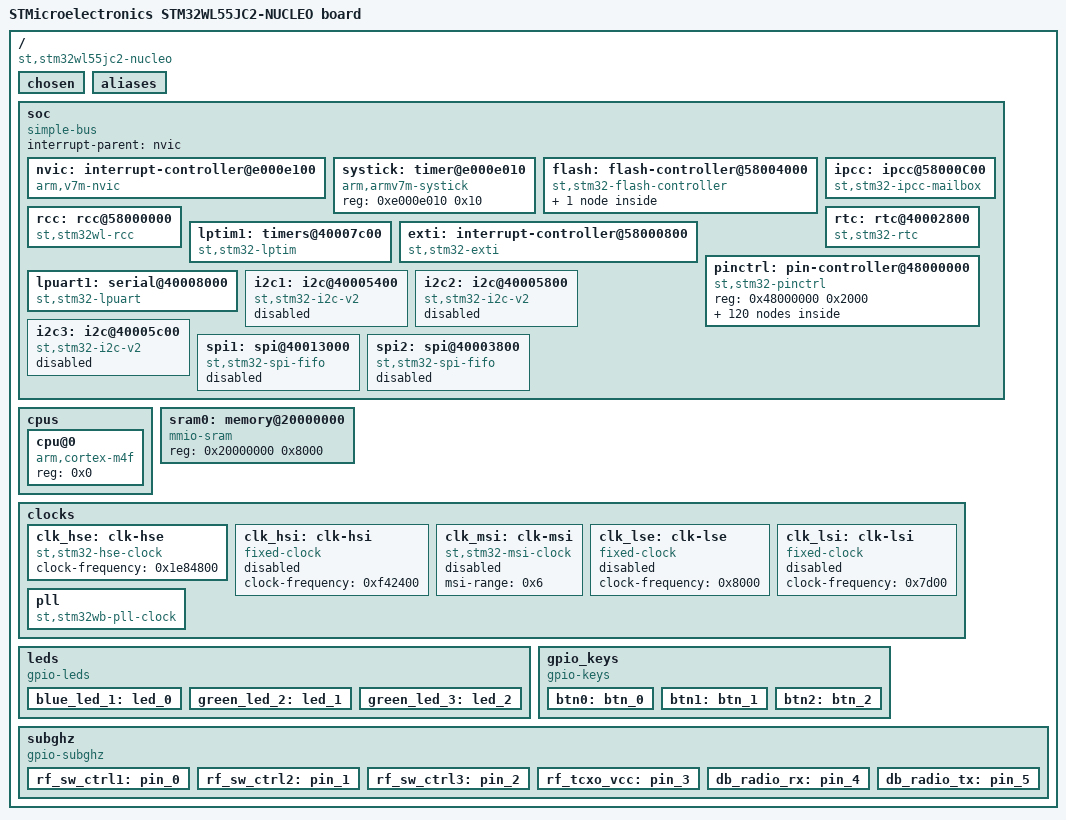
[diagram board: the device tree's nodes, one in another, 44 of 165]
/dts-v1/;

/ {
	#address-cells = < 0x1 >;
	#size-cells = < 0x1 >;
	model = "STMicroelectronics STM32WL55JC2-NUCLEO board";
	compatible = "st,stm32wl55jc2-nucleo";
	chosen {
		zephyr,flash-controller = &flash;
		zephyr,console = &lpuart1;
		zephyr,shell-uart = &lpuart1;
		zephyr,sram = &sram0;
		zephyr,flash = &flash0;
		zephyr,code-partition = &flash0;
	};
	aliases {
		led0 = &green_led_2;
		sw0 = &btn0;
		sw1 = &btn1;
		sw2 = &btn2;
		rfswctrl1 = &rf_sw_ctrl1;
		rfswctrl2 = &rf_sw_ctrl2;
		rfswctrl3 = &rf_sw_ctrl3;
		rftcxovcc = &rf_tcxo_vcc;
		dbradiorx = &db_radio_rx;
		dbradiotx = &db_radio_tx;
	};
	soc {
		#address-cells = < 0x1 >;
		#size-cells = < 0x1 >;
		compatible = "simple-bus";
		interrupt-parent = < &nvic >;
		ranges;
		nvic: interrupt-controller@e000e100 {
			compatible = "arm,v7m-nvic";
			reg = < 0xe000e100 0xc00 >;
			interrupt-controller;
			#interrupt-cells = < 0x2 >;
			arm,num-irq-priority-bits = < 0x4 >;
			phandle = < 0x1 >;
		};
		systick: timer@e000e010 {
			compatible = "arm,armv7m-systick";
			reg = < 0xe000e010 0x10 >;
		};
		flash: flash-controller@58004000 {
			compatible = "st,stm32-flash-controller", "st,stm32wl-flash-controller";
			label = "FLASH_CTRL";
			reg = < 0x58004000 0x400 >;
			interrupts = < 0x4 0x0 >;
			#address-cells = < 0x1 >;
			#size-cells = < 0x1 >;
			flash0: flash@8000000 {
				compatible = "soc-nv-flash";
				label = "FLASH_STM32";
				write-block-size = < 0x8 >;
				erase-block-size = < 0x800 >;
				reg = < 0x8000000 0x20000 >;
			};
		};
		ipcc: ipcc@58000C00 {
			compatible = "st,stm32-ipcc-mailbox";
			#address-cells = < 0x1 >;
			#size-cells = < 0x0 >;
			reg = < 0x58000c00 0x10 >;
			clocks = < &rcc 0x6 0x100000 >;
			interrupts = < 0x2d 0x0 >, < 0x2e 0x0 >;
			interrupt-names = "rxo", "txf";
			status = "okay";
			label = "IPCC";
			buffer = < 0x20000000 0xff >;
		};
		rcc: rcc@58000000 {
			compatible = "st,stm32wl-rcc";
			#clock-cells = < 0x2 >;
			reg = < 0x58000000 0x400 >;
			label = "STM32_CLK_RCC";
			clocks = < &pll >;
			clock-frequency = < 0x2dc6c00 >;
			cpu1-prescaler = < 0x1 >;
			cpu2-prescaler = < 0x1 >;
			ahb3-prescaler = < 0x1 >;
			apb1-prescaler = < 0x1 >;
			apb2-prescaler = < 0x1 >;
			phandle = < 0x2 >;
		};
		rtc: rtc@40002800 {
			compatible = "st,stm32-rtc";
			reg = < 0x40002800 0x400 >;
			interrupts = < 0x2a 0x0 >;
			clocks = < &rcc 0x2 0x10000000 >;
			prescaler = < 0x8000 >;
			status = "okay";
			label = "RTC_0";
		};
		lptim1: timers@40007c00 {
			compatible = "st,stm32-lptim";
			clocks = < &rcc 0x2 0x48000000 >;
			#address-cells = < 0x1 >;
			#size-cells = < 0x0 >;
			reg = < 0x40007c00 0x400 >;
			interrupts = < 0x27 0x0 >;
			interrupt-names = "wakeup";
			status = "okay";
			label = "LPTIM_1";
		};
		exti: interrupt-controller@58000800 {
			compatible = "st,stm32-exti";
			interrupt-controller;
			#interrupt-cells = < 0x1 >;
			reg = < 0x58000800 0x400 >;
		};
		pinctrl: pin-controller@48000000 {
			compatible = "st,stm32-pinctrl";
			#address-cells = < 0x1 >;
			#size-cells = < 0x1 >;
			reg = < 0x48000000 0x2000 >;
			gpioa: gpio@48000000 {
				compatible = "st,stm32-gpio";
				gpio-controller;
				#gpio-cells = < 0x2 >;
				reg = < 0x48000000 0x400 >;
				clocks = < &rcc 0x1 0x1 >;
				label = "GPIOA";
				phandle = < 0xe >;
			};
			gpiob: gpio@48000400 {
				compatible = "st,stm32-gpio";
				gpio-controller;
				#gpio-cells = < 0x2 >;
				reg = < 0x48000400 0x400 >;
				clocks = < &rcc 0x1 0x2 >;
				label = "GPIOB";
				phandle = < 0xd >;
			};
			gpioc: gpio@48000800 {
				compatible = "st,stm32-gpio";
				gpio-controller;
				#gpio-cells = < 0x2 >;
				reg = < 0x48000800 0x400 >;
				clocks = < &rcc 0x1 0x4 >;
				label = "GPIOC";
				phandle = < 0xf >;
			};
			gpioh: gpio@48001c00 {
				compatible = "st,stm32-gpio";
				gpio-controller;
				#gpio-cells = < 0x2 >;
				reg = < 0x48001c00 0x400 >;
				clocks = < &rcc 0x1 0x80 >;
				label = "GPIOH";
			};
			adc_in6_pa10: adc_in6_pa10 {
				pinmux = < 0xa10 >;
			};
			adc_in7_pa11: adc_in7_pa11 {
				pinmux = < 0xb10 >;
			};
			adc_in8_pa12: adc_in8_pa12 {
				pinmux = < 0xc10 >;
			};
			adc_in9_pa13: adc_in9_pa13 {
				pinmux = < 0xd10 >;
			};
			adc_in10_pa14: adc_in10_pa14 {
				pinmux = < 0xe10 >;
			};
			adc_in11_pa15: adc_in11_pa15 {
				pinmux = < 0xf10 >;
			};
			adc_in5_pb1: adc_in5_pb1 {
				pinmux = < 0x1110 >;
			};
			adc_in4_pb2: adc_in4_pb2 {
				pinmux = < 0x1210 >;
			};
			adc_in2_pb3: adc_in2_pb3 {
				pinmux = < 0x1310 >;
			};
			adc_in3_pb4: adc_in3_pb4 {
				pinmux = < 0x1410 >;
			};
			adc_in0_pb13: adc_in0_pb13 {
				pinmux = < 0x1d10 >;
			};
			adc_in1_pb14: adc_in1_pb14 {
				pinmux = < 0x1e10 >;
			};
			dac_out1_pa10: dac_out1_pa10 {
				pinmux = < 0xa10 >;
			};
			i2c1_scl_pa9: i2c1_scl_pa9 {
				pinmux = < 0x904 >;
				bias-pull-up;
				drive-open-drain;
			};
			i2c1_scl_pb6: i2c1_scl_pb6 {
				pinmux = < 0x1604 >;
				bias-pull-up;
				drive-open-drain;
			};
			i2c1_scl_pb8: i2c1_scl_pb8 {
				pinmux = < 0x1804 >;
				bias-pull-up;
				drive-open-drain;
			};
			i2c2_scl_pa12: i2c2_scl_pa12 {
				pinmux = < 0xc04 >;
				bias-pull-up;
				drive-open-drain;
				phandle = < 0x6 >;
			};
			i2c2_scl_pb15: i2c2_scl_pb15 {
				pinmux = < 0x1f04 >;
				bias-pull-up;
				drive-open-drain;
			};
			i2c3_scl_pa7: i2c3_scl_pa7 {
				pinmux = < 0x704 >;
				bias-pull-up;
				drive-open-drain;
			};
			i2c3_scl_pb10: i2c3_scl_pb10 {
				pinmux = < 0x1a04 >;
				bias-pull-up;
				drive-open-drain;
			};
			i2c3_scl_pb13: i2c3_scl_pb13 {
				pinmux = < 0x1d04 >;
				bias-pull-up;
				drive-open-drain;
			};
			i2c3_scl_pc0: i2c3_scl_pc0 {
				pinmux = < 0x2004 >;
				bias-pull-up;
				drive-open-drain;
			};
			i2c1_sda_pa10: i2c1_sda_pa10 {
				pinmux = < 0xa04 >;
				bias-pull-up;
				drive-open-drain;
			};
			i2c1_sda_pb7: i2c1_sda_pb7 {
				pinmux = < 0x1704 >;
				bias-pull-up;
				drive-open-drain;
			};
			i2c1_sda_pb9: i2c1_sda_pb9 {
				pinmux = < 0x1904 >;
				bias-pull-up;
				drive-open-drain;
			};
			i2c2_sda_pa11: i2c2_sda_pa11 {
				pinmux = < 0xb04 >;
				bias-pull-up;
				drive-open-drain;
				phandle = < 0x7 >;
			};
			i2c2_sda_pa15: i2c2_sda_pa15 {
				pinmux = < 0xf04 >;
				bias-pull-up;
				drive-open-drain;
			};
			i2c3_sda_pb4: i2c3_sda_pb4 {
				pinmux = < 0x1404 >;
				bias-pull-up;
				drive-open-drain;
			};
			i2c3_sda_pb11: i2c3_sda_pb11 {
				pinmux = < 0x1b04 >;
				bias-pull-up;
				drive-open-drain;
			};
			i2c3_sda_pb14: i2c3_sda_pb14 {
				pinmux = < 0x1e04 >;
				bias-pull-up;
				drive-open-drain;
			};
			i2c3_sda_pc1: i2c3_sda_pc1 {
				pinmux = < 0x2104 >;
				bias-pull-up;
				drive-open-drain;
			};
			i2s2_ck_pa8: i2s2_ck_pa8 {
				pinmux = < 0x805 >;
				slew-rate = "very-high-speed";
			};
			i2s2_ck_pa9: i2s2_ck_pa9 {
				pinmux = < 0x905 >;
				slew-rate = "very-high-speed";
			};
			i2s2_ck_pb10: i2s2_ck_pb10 {
				pinmux = < 0x1a05 >;
				slew-rate = "very-high-speed";
			};
			i2s2_ck_pb13: i2s2_ck_pb13 {
				pinmux = < 0x1d05 >;
				slew-rate = "very-high-speed";
			};
			i2s2_sd_pa10: i2s2_sd_pa10 {
				pinmux = < 0xa05 >;
			};
			i2s2_sd_pb15: i2s2_sd_pb15 {
				pinmux = < 0x1f05 >;
			};
			i2s2_sd_pc1: i2s2_sd_pc1 {
				pinmux = < 0x2103 >;
			};
			i2s2_sd_pc3: i2s2_sd_pc3 {
				pinmux = < 0x2305 >;
			};
			i2s2_ws_pa9: i2s2_ws_pa9 {
				pinmux = < 0x903 >;
			};
			i2s2_ws_pb9: i2s2_ws_pb9 {
				pinmux = < 0x1905 >;
			};
			i2s2_ws_pb12: i2s2_ws_pb12 {
				pinmux = < 0x1c05 >;
			};
			spi1_miso_pa6: spi1_miso_pa6 {
				pinmux = < 0x605 >;
				bias-pull-down;
				phandle = < 0xa >;
			};
			spi1_miso_pa11: spi1_miso_pa11 {
				pinmux = < 0xb05 >;
				bias-pull-down;
			};
			spi1_miso_pb4: spi1_miso_pb4 {
				pinmux = < 0x1405 >;
				bias-pull-down;
			};
			spi2_miso_pa5: spi2_miso_pa5 {
				pinmux = < 0x503 >;
				bias-pull-down;
			};
			spi2_miso_pb14: spi2_miso_pb14 {
				pinmux = < 0x1e05 >;
				bias-pull-down;
			};
			spi2_miso_pc2: spi2_miso_pc2 {
				pinmux = < 0x2205 >;
				bias-pull-down;
			};
			spi1_mosi_pa7: spi1_mosi_pa7 {
				pinmux = < 0x705 >;
				bias-pull-down;
				phandle = < 0xb >;
			};
			spi1_mosi_pa12: spi1_mosi_pa12 {
				pinmux = < 0xc05 >;
				bias-pull-down;
			};
			spi1_mosi_pb5: spi1_mosi_pb5 {
				pinmux = < 0x1505 >;
				bias-pull-down;
			};
			spi2_mosi_pa10: spi2_mosi_pa10 {
				pinmux = < 0xa05 >;
				bias-pull-down;
			};
			spi2_mosi_pb15: spi2_mosi_pb15 {
				pinmux = < 0x1f05 >;
				bias-pull-down;
			};
			spi2_mosi_pc1: spi2_mosi_pc1 {
				pinmux = < 0x2103 >;
				bias-pull-down;
			};
			spi2_mosi_pc3: spi2_mosi_pc3 {
				pinmux = < 0x2305 >;
				bias-pull-down;
			};
			spi1_nss_pa4: spi1_nss_pa4 {
				pinmux = < 0x405 >;
				bias-pull-up;
				phandle = < 0x8 >;
			};
			spi1_nss_pa15: spi1_nss_pa15 {
				pinmux = < 0xf05 >;
				bias-pull-up;
			};
			spi1_nss_pb2: spi1_nss_pb2 {
				pinmux = < 0x1205 >;
				bias-pull-up;
			};
			spi2_nss_pa9: spi2_nss_pa9 {
				pinmux = < 0x903 >;
				bias-pull-up;
			};
			spi2_nss_pb9: spi2_nss_pb9 {
				pinmux = < 0x1905 >;
				bias-pull-up;
			};
			spi2_nss_pb12: spi2_nss_pb12 {
				pinmux = < 0x1c05 >;
				bias-pull-up;
			};
			spi1_sck_pa1: spi1_sck_pa1 {
				pinmux = < 0x105 >;
				slew-rate = "very-high-speed";
			};
			spi1_sck_pa5: spi1_sck_pa5 {
				pinmux = < 0x505 >;
				slew-rate = "very-high-speed";
				phandle = < 0x9 >;
			};
			spi1_sck_pb3: spi1_sck_pb3 {
				pinmux = < 0x1305 >;
				slew-rate = "very-high-speed";
			};
			spi2_sck_pa8: spi2_sck_pa8 {
				pinmux = < 0x805 >;
				slew-rate = "very-high-speed";
			};
			spi2_sck_pa9: spi2_sck_pa9 {
				pinmux = < 0x905 >;
				slew-rate = "very-high-speed";
			};
			spi2_sck_pb10: spi2_sck_pb10 {
				pinmux = < 0x1a05 >;
				slew-rate = "very-high-speed";
			};
			spi2_sck_pb13: spi2_sck_pb13 {
				pinmux = < 0x1d05 >;
				slew-rate = "very-high-speed";
			};
			tim1_ch1n_pa7: tim1_ch1n_pa7 {
				pinmux = < 0x701 >;
			};
			tim1_ch1_pa8: tim1_ch1_pa8 {
				pinmux = < 0x801 >;
			};
			tim1_ch2_pa9: tim1_ch2_pa9 {
				pinmux = < 0x901 >;
			};
			tim1_ch3_pa10: tim1_ch3_pa10 {
				pinmux = < 0xa01 >;
			};
			tim1_ch4_pa11: tim1_ch4_pa11 {
				pinmux = < 0xb01 >;
			};
			tim1_ch2n_pb8: tim1_ch2n_pb8 {
				pinmux = < 0x1801 >;
			};
			tim1_ch3n_pb9: tim1_ch3n_pb9 {
				pinmux = < 0x1901 >;
			};
			tim1_ch1n_pb13: tim1_ch1n_pb13 {
				pinmux = < 0x1d01 >;
			};
			tim1_ch2n_pb14: tim1_ch2n_pb14 {
				pinmux = < 0x1e01 >;
			};
			tim1_ch3n_pb15: tim1_ch3n_pb15 {
				pinmux = < 0x1f01 >;
			};
			tim2_ch1_pa0: tim2_ch1_pa0 {
				pinmux = < 0x1 >;
			};
			tim2_ch2_pa1: tim2_ch2_pa1 {
				pinmux = < 0x101 >;
			};
			tim2_ch3_pa2: tim2_ch3_pa2 {
				pinmux = < 0x201 >;
			};
			tim2_ch4_pa3: tim2_ch4_pa3 {
				pinmux = < 0x301 >;
			};
			tim2_ch1_pa5: tim2_ch1_pa5 {
				pinmux = < 0x501 >;
			};
			tim2_ch1_pa15: tim2_ch1_pa15 {
				pinmux = < 0xf01 >;
			};
			tim2_ch2_pb3: tim2_ch2_pb3 {
				pinmux = < 0x1301 >;
			};
			tim2_ch3_pb10: tim2_ch3_pb10 {
				pinmux = < 0x1a01 >;
			};
			tim2_ch4_pb11: tim2_ch4_pb11 {
				pinmux = < 0x1b01 >;
			};
			tim16_ch1_pa6: tim16_ch1_pa6 {
				pinmux = < 0x60e >;
			};
			tim16_ch1n_pb6: tim16_ch1n_pb6 {
				pinmux = < 0x160e >;
			};
			tim16_ch1_pb8: tim16_ch1_pb8 {
				pinmux = < 0x180e >;
			};
			tim17_ch1_pa7: tim17_ch1_pa7 {
				pinmux = < 0x70e >;
			};
			tim17_ch1n_pb7: tim17_ch1n_pb7 {
				pinmux = < 0x170e >;
			};
			tim17_ch1_pb9: tim17_ch1_pb9 {
				pinmux = < 0x190e >;
			};
			lpuart1_cts_pa6: lpuart1_cts_pa6 {
				pinmux = < 0x608 >;
				bias-pull-up;
				drive-open-drain;
			};
			usart1_cts_pa11: usart1_cts_pa11 {
				pinmux = < 0xb07 >;
				bias-pull-up;
				drive-open-drain;
			};
			usart1_cts_pb4: usart1_cts_pb4 {
				pinmux = < 0x1407 >;
				bias-pull-up;
				drive-open-drain;
			};
			lpuart1_cts_pb13: lpuart1_cts_pb13 {
				pinmux = < 0x1d08 >;
				bias-pull-up;
				drive-open-drain;
			};
			usart2_cts_pa0: usart2_cts_pa0 {
				pinmux = < 0x7 >;
				bias-pull-up;
				drive-open-drain;
			};
			lpuart1_rts_pa1: lpuart1_rts_pa1 {
				pinmux = < 0x108 >;
				bias-pull-up;
				drive-open-drain;
			};
			usart1_rts_pa12: usart1_rts_pa12 {
				pinmux = < 0xc07 >;
				bias-pull-up;
				drive-open-drain;
			};
			lpuart1_rts_pb1: lpuart1_rts_pb1 {
				pinmux = < 0x1108 >;
				bias-pull-up;
				drive-open-drain;
			};
			usart1_rts_pb3: usart1_rts_pb3 {
				pinmux = < 0x1307 >;
				bias-pull-up;
				drive-open-drain;
			};
			lpuart1_rts_pb12: lpuart1_rts_pb12 {
				pinmux = < 0x1c08 >;
				bias-pull-up;
				drive-open-drain;
			};
			usart2_rts_pa1: usart2_rts_pa1 {
				pinmux = < 0x107 >;
				bias-pull-up;
				drive-open-drain;
			};
			lpuart1_rx_pa3: lpuart1_rx_pa3 {
				pinmux = < 0x308 >;
				phandle = < 0x5 >;
			};
			usart1_rx_pa10: usart1_rx_pa10 {
				pinmux = < 0xa07 >;
			};
			usart1_rx_pb7: usart1_rx_pb7 {
				pinmux = < 0x1707 >;
			};
			lpuart1_rx_pb10: lpuart1_rx_pb10 {
				pinmux = < 0x1a08 >;
			};
			lpuart1_rx_pc0: lpuart1_rx_pc0 {
				pinmux = < 0x2008 >;
			};
			usart2_rx_pa3: usart2_rx_pa3 {
				pinmux = < 0x307 >;
			};
			lpuart1_tx_pa2: lpuart1_tx_pa2 {
				pinmux = < 0x208 >;
				bias-pull-up;
				phandle = < 0x4 >;
			};
			usart1_tx_pa9: usart1_tx_pa9 {
				pinmux = < 0x907 >;
				bias-pull-up;
			};
			usart1_tx_pb6: usart1_tx_pb6 {
				pinmux = < 0x1607 >;
				bias-pull-up;
			};
			lpuart1_tx_pb11: lpuart1_tx_pb11 {
				pinmux = < 0x1b08 >;
				bias-pull-up;
			};
			lpuart1_tx_pc1: lpuart1_tx_pc1 {
				pinmux = < 0x2108 >;
				bias-pull-up;
			};
			usart2_tx_pa2: usart2_tx_pa2 {
				pinmux = < 0x207 >;
				bias-pull-up;
			};
		};
		lpuart1: serial@40008000 {
			compatible = "st,stm32-lpuart", "st,stm32-uart";
			reg = < 0x40008000 0x400 >;
			clocks = < &rcc 0x4 0x1 >;
			interrupts = < 0x26 0x0 >;
			status = "okay";
			label = "LPUART_1";
			pinctrl-0 = < &lpuart1_tx_pa2 &lpuart1_rx_pa3 >;
			current-speed = < 0x1c200 >;
		};
		i2c1: i2c@40005400 {
			compatible = "st,stm32-i2c-v2";
			clock-frequency = < 0x186a0 >;
			#address-cells = < 0x1 >;
			#size-cells = < 0x0 >;
			reg = < 0x40005400 0x400 >;
			clocks = < &rcc 0x2 0x200000 >;
			interrupts = < 0x1e 0x0 >, < 0x1f 0x0 >;
			interrupt-names = "event", "error";
			status = "disabled";
			label = "I2C_1";
		};
		i2c2: i2c@40005800 {
			compatible = "st,stm32-i2c-v2";
			clock-frequency = < 0x61a80 >;
			#address-cells = < 0x1 >;
			#size-cells = < 0x0 >;
			reg = < 0x40005800 0x400 >;
			clocks = < &rcc 0x2 0x400000 >;
			interrupts = < 0x20 0x0 >, < 0x21 0x0 >;
			interrupt-names = "event", "error";
			status = "disabled";
			label = "I2C_2";
			pinctrl-0 = < &i2c2_scl_pa12 &i2c2_sda_pa11 >;
		};
		i2c3: i2c@40005c00 {
			compatible = "st,stm32-i2c-v2";
			clock-frequency = < 0x186a0 >;
			#address-cells = < 0x1 >;
			#size-cells = < 0x0 >;
			reg = < 0x40005c00 0x400 >;
			clocks = < &rcc 0x2 0x800000 >;
			interrupts = < 0x30 0x0 >, < 0x31 0x0 >;
			interrupt-names = "event", "error";
			status = "disabled";
			label = "I2C_3";
		};
		spi1: spi@40013000 {
			compatible = "st,stm32-spi-fifo", "st,stm32-spi";
			#address-cells = < 0x1 >;
			#size-cells = < 0x0 >;
			reg = < 0x40013000 0x400 >;
			interrupts = < 0x22 0x5 >;
			clocks = < &rcc 0x3 0x1000 >;
			status = "disabled";
			label = "SPI_1";
			pinctrl-0 = < &spi1_nss_pa4 &spi1_sck_pa5 &spi1_miso_pa6 &spi1_mosi_pa7 >;
		};
		spi2: spi@40003800 {
			compatible = "st,stm32-spi-fifo", "st,stm32-spi";
			#address-cells = < 0x1 >;
			#size-cells = < 0x0 >;
			reg = < 0x40003800 0x400 >;
			interrupts = < 0x23 0x5 >;
			clocks = < &rcc 0x2 0x4000 >;
			status = "disabled";
			label = "SPI_2";
		};
	};
	cpus {
		#address-cells = < 0x1 >;
		#size-cells = < 0x0 >;
		cpu@0 {
			device_type = "cpu";
			compatible = "arm,cortex-m4f";
			reg = < 0x0 >;
		};
	};
	sram0: memory@20000000 {
		compatible = "mmio-sram";
		reg = < 0x20000000 0x8000 >;
	};
	clocks {
		clk_hse: clk-hse {
			#clock-cells = < 0x0 >;
			compatible = "st,stm32-hse-clock";
			clock-frequency = < 0x1e84800 >;
			status = "okay";
			phandle = < 0xc >;
		};
		clk_hsi: clk-hsi {
			#clock-cells = < 0x0 >;
			compatible = "fixed-clock";
			clock-frequency = < 0xf42400 >;
			status = "disabled";
		};
		clk_msi: clk-msi {
			#clock-cells = < 0x0 >;
			compatible = "st,stm32-msi-clock";
			msi-range = < 0x6 >;
			status = "disabled";
		};
		clk_lse: clk-lse {
			#clock-cells = < 0x0 >;
			compatible = "fixed-clock";
			clock-frequency = < 0x8000 >;
			status = "disabled";
		};
		clk_lsi: clk-lsi {
			#clock-cells = < 0x0 >;
			compatible = "fixed-clock";
			clock-frequency = < 0x7d00 >;
			status = "disabled";
		};
		pll: pll {
			#clock-cells = < 0x0 >;
			compatible = "st,stm32wb-pll-clock";
			status = "okay";
			div-m = < 0x2 >;
			mul-n = < 0x6 >;
			div-r = < 0x2 >;
			clocks = < &clk_hse >;
			phandle = < 0x3 >;
		};
	};
	leds {
		compatible = "gpio-leds";
		blue_led_1: led_0 {
			gpios = < &gpiob 0xf 0x0 >;
			label = "LED_0";
		};
		green_led_2: led_1 {
			gpios = < &gpiob 0x9 0x0 >;
			label = "LED_1";
		};
		green_led_3: led_2 {
			gpios = < &gpiob 0xb 0x0 >;
			label = "LED_2";
		};
	};
	gpio_keys {
		compatible = "gpio-keys";
		btn0: btn_0 {
			label = "BTN_0";
			gpios = < &gpioa 0x0 0x11 >;
		};
		btn1: btn_1 {
			label = "BTN_1";
			gpios = < &gpioa 0x1 0x11 >;
		};
		btn2: btn_2 {
			label = "BTN_2";
			gpios = < &gpioc 0x6 0x11 >;
		};
	};
	subghz {
		compatible = "gpio-subghz";
		rf_sw_ctrl1: pin_0 {
			gpios = < &gpioc 0x4 0x1 >;
			label = "RF_SW_CTRL1";
		};
		rf_sw_ctrl2: pin_1 {
			gpios = < &gpioc 0x5 0x1 >;
			label = "RF_SW_CTRL2";
		};
		rf_sw_ctrl3: pin_2 {
			gpios = < &gpioc 0x3 0x1 >;
			label = "RF_SW_CTRL3";
		};
		rf_tcxo_vcc: pin_3 {
			gpios = < &gpiob 0x0 0x1 >;
			label = "RF_TXCO_VCC";
		};
		db_radio_rx: pin_4 {
			gpios = < &gpiob 0xc 0x1 >;
			label = "DB_RADIO_RX";
		};
		db_radio_tx: pin_5 {
			gpios = < &gpiob 0xd 0x1 >;
			label = "DB_RADIO_TX";
		};
	};
};
